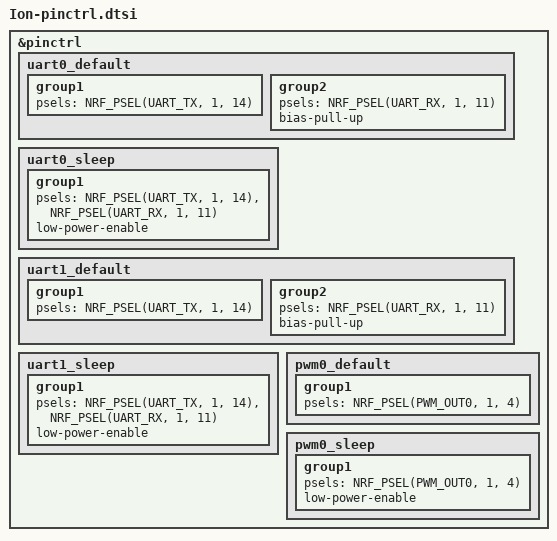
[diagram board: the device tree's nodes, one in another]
&pinctrl {
    uart0_default: uart0_default {
		group1 {
			psels = <NRF_PSEL(UART_TX, 1, 14)>;
		};
		group2 {
			psels = <NRF_PSEL(UART_RX, 1, 11)>;
			bias-pull-up;
		};
	};

	uart0_sleep: uart0_sleep {
		group1 {
			psels = <NRF_PSEL(UART_TX, 1, 14)>,
				<NRF_PSEL(UART_RX, 1, 11)>;
			low-power-enable;
		};
	};

	uart1_default: uart1_default {
		group1 {
			psels = <NRF_PSEL(UART_TX, 1, 14)>;
		};
		group2 {
			psels = <NRF_PSEL(UART_RX, 1, 11)>;
			bias-pull-up;
		};
	};

	uart1_sleep: uart1_sleep {
		group1 {
			psels = <NRF_PSEL(UART_TX, 1, 14)>,
				<NRF_PSEL(UART_RX, 1, 11)>;
			low-power-enable;
		};
	};

	pwm0_default: pwm0_default {
		group1 {
			psels = <NRF_PSEL(PWM_OUT0, 1, 4)>;
		};
	};

	pwm0_sleep: pwm0_sleep {
		group1 {
			psels = <NRF_PSEL(PWM_OUT0, 1, 4)>;
			low-power-enable;
		};
	};
};
